AUTOSAR XML (schema 4-2-2)
package /Components
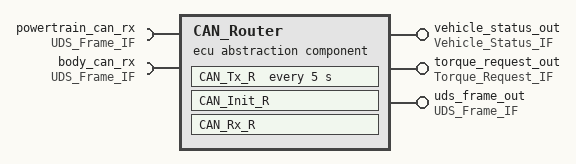
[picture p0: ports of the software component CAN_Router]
  ecu abstraction sw component type CAN_Router
    provide port vehicle_status_out: provided-interface=Vehicle_Status_IF
    provide port torque_request_out: provided-interface=Torque_Request_IF
    provide port uds_frame_out: provided-interface=UDS_Frame_IF
    require port powertrain_can_rx: required-interface=UDS_Frame_IF
    require port body_can_rx: required-interface=UDS_Frame_IF
    behavior CAN_Router_InternalBehavior
      data received event CAN_Rx_Event: start-on-event=CAN_Rx_R
      init event CAN_Init: start-on-event=CAN_Init_R
      timing event CAN_Periodic_5ms: start-on-event=CAN_Tx_R, period=5
      runnable CAN_Init_R
        data-receive-point-by-arguments:
          access VA_Init_BodyUdsReqArg: accessed-variable=body_can_rx.uds_request_frame
        data-receive-point-by-values:
          access VA_Init_PowerUdsRespVal: accessed-variable=powertrain_can_rx.uds_response_frame
        data-send-points:
          access VA_Init_UdsFrameOutResp: accessed-variable=uds_frame_out.uds_response_frame
        parameter access PA_Init_RouteConfig1: accessed-parameter=vehicle_status_out.vehicle_speed_kph
      runnable CAN_Rx_R: minimum-start-interval=1
        data-receive-point-by-arguments:
          access VA_Rx_PowerUdsReqArg: accessed-variable=powertrain_can_rx.uds_request_frame
          access VA_Rx_BodyUdsRespArg: accessed-variable=body_can_rx.uds_response_frame
        data-receive-point-by-values:
          access VA_Rx_PowerUdsReqVal: accessed-variable=powertrain_can_rx.uds_request_frame
          access VA_Rx_BodyUdsRespVal: accessed-variable=body_can_rx.uds_response_frame
        data-send-points:
          4 x access:
            VA_Rx_VehSpeedOut: accessed-variable=vehicle_status_out.vehicle_speed_kph
            VA_Rx_BrakeStatusOut: accessed-variable=vehicle_status_out.brake_status
            VA_Rx_EngineRpmOut: accessed-variable=vehicle_status_out.engine_rpm
            VA_Rx_DriverTorqueOut: accessed-variable=torque_request_out.driver_torque_request_nm
        parameter access PA_Rx_DefaultTorqueParam: accessed-parameter=torque_request_out.driver_torque_request_nm
      runnable CAN_Tx_R: minimum-start-interval=1
        data-receive-point-by-arguments:
          access VA_Tx_UdsRespArg: accessed-variable=powertrain_can_rx.uds_response_frame
        data-receive-point-by-values:
          access VA_Tx_UdsReqVal: accessed-variable=body_can_rx.uds_request_frame
        data-send-points:
          access VA_Tx_UdsOutReq: accessed-variable=uds_frame_out.uds_request_frame
          access VA_Tx_UdsOutResp: accessed-variable=uds_frame_out.uds_response_frame
        parameter access PA_Tx_Config1: accessed-parameter=torque_request_out.driver_torque_request_nm
